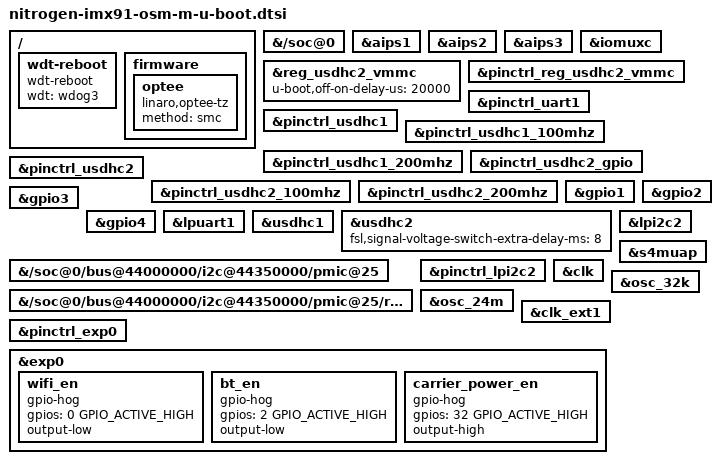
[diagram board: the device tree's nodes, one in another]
// SPDX-License-Identifier: GPL-2.0+
/*
 * Copyright 2025 Ezurio LLC
 */

#include "imx91-u-boot.dtsi"

/ {
	wdt-reboot {
		compatible = "wdt-reboot";
		wdt = <&wdog3>;
		bootph-pre-ram;
		bootph-some-ram;
	};

	firmware {
		optee {
			compatible = "linaro,optee-tz";
			method = "smc";
		};
	};
};

&{/soc@0} {
	bootph-all;
	bootph-pre-ram;
};

&aips1 {
	bootph-pre-ram;
	bootph-all;
};

&aips2 {
	bootph-pre-ram;
	bootph-some-ram;
};

&aips3 {
	bootph-pre-ram;
	bootph-some-ram;
};

&iomuxc {
	bootph-pre-ram;
	bootph-some-ram;
};

&reg_usdhc2_vmmc {
	u-boot,off-on-delay-us = <20000>;
	bootph-pre-ram;
	bootph-some-ram;
};

&pinctrl_reg_usdhc2_vmmc {
	bootph-pre-ram;
};

&pinctrl_uart1 {
	bootph-pre-ram;
	bootph-some-ram;
};

&pinctrl_usdhc1 {
	bootph-pre-ram;
	bootph-some-ram;
};

&pinctrl_usdhc1_100mhz {
	bootph-pre-ram;
	bootph-some-ram;
};

&pinctrl_usdhc1_200mhz {
	bootph-pre-ram;
	bootph-some-ram;
};

&pinctrl_usdhc2_gpio {
	bootph-pre-ram;
	bootph-some-ram;
};

&pinctrl_usdhc2 {
	bootph-pre-ram;
	bootph-some-ram;
};

&pinctrl_usdhc2_100mhz {
	bootph-pre-ram;
	bootph-some-ram;
};

&pinctrl_usdhc2_200mhz {
	bootph-pre-ram;
	bootph-some-ram;
};

&gpio1 {
	bootph-pre-ram;
	bootph-some-ram;
};

&gpio2 {
	bootph-pre-ram;
	bootph-some-ram;
};

&gpio3 {
	bootph-pre-ram;
	bootph-some-ram;
};

&gpio4 {
	bootph-pre-ram;
	bootph-some-ram;
};

&lpuart1 {
	bootph-pre-ram;
	bootph-some-ram;
};

&usdhc1 {
	bootph-pre-ram;
	bootph-some-ram;
};

&usdhc2 {
	bootph-pre-ram;
	bootph-some-ram;
	fsl,signal-voltage-switch-extra-delay-ms = <8>;
};

&lpi2c2 {
	bootph-pre-ram;
	bootph-some-ram;
};

&{/soc@0/bus@44000000/i2c@44350000/pmic@25} {
	bootph-pre-ram;
	bootph-some-ram;
};

&{/soc@0/bus@44000000/i2c@44350000/pmic@25/regulators} {
	bootph-pre-ram;
	bootph-some-ram;
};

&pinctrl_lpi2c2 {
	bootph-pre-ram;
	bootph-some-ram;
};

&s4muap {
	bootph-pre-ram;
	bootph-some-ram;
	status = "okay";
};

&clk {
	bootph-all;
	bootph-pre-ram;
	/delete-property/ assigned-clocks;
	/delete-property/ assigned-clock-rates;
	/delete-property/ assigned-clock-parents;
};

&osc_32k {
	bootph-all;
	bootph-pre-ram;
};

&osc_24m {
	bootph-all;
	bootph-pre-ram;
};

&clk_ext1 {
	bootph-all;
	bootph-pre-ram;
};

&pinctrl_exp0 {
	bootph-all;
};

&exp0 {
	bootph-all;

	wifi_en {
		bootph-all;
		gpio-hog;
		gpios = <0 GPIO_ACTIVE_HIGH>;
		output-low;
	};

	bt_en {
		bootph-all;
		gpio-hog;
		gpios = <2 GPIO_ACTIVE_HIGH>;
		output-low;
	};

	carrier_power_en {
		bootph-all;
		gpio-hog;
		gpios = <32 GPIO_ACTIVE_HIGH>;
		output-high;
	};
};
